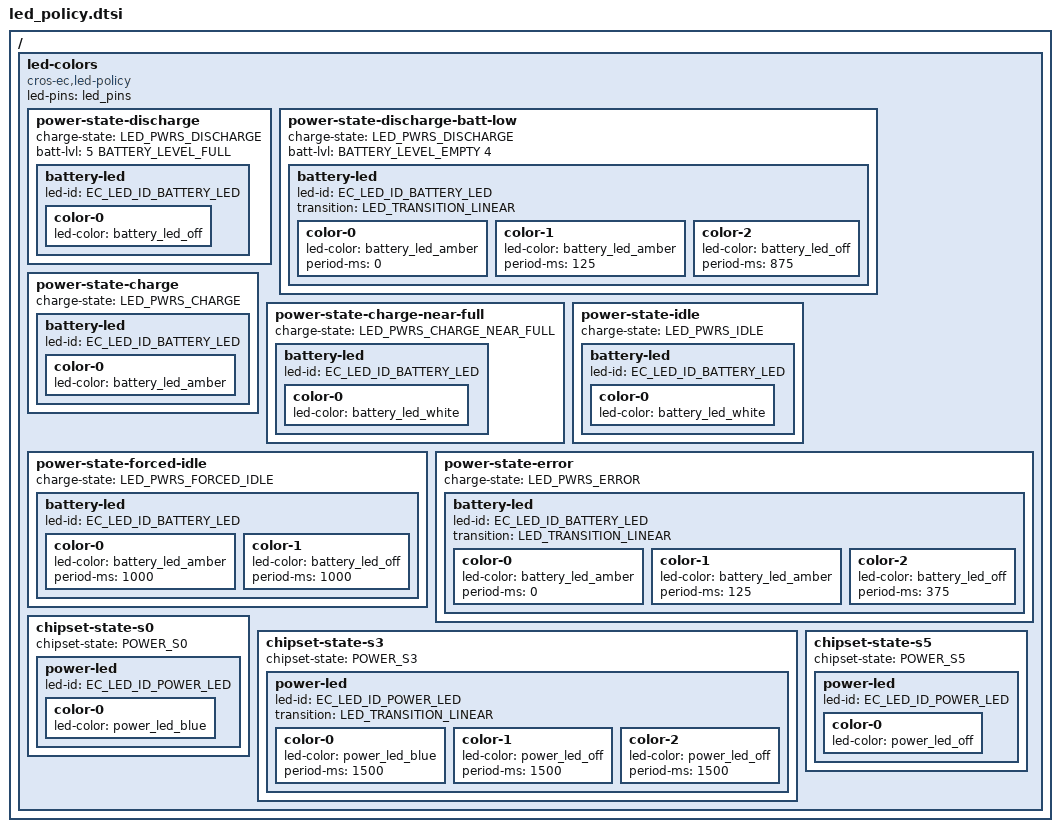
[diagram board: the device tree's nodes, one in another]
#include <dt-bindings/battery.h>

/ {
	led-colors {
		compatible = "cros-ec,led-policy";
		led-pins = <&led_pins>;

		/* --------------------------------------------------
		 * DC MODE (DISCHARGE)
		 * -------------------------------------------------- */

		/* On battery only (discharge): default off */
		power-state-discharge {
			charge-state = "LED_PWRS_DISCHARGE";
			batt-lvl = <5 BATTERY_LEVEL_FULL>;

			battery-led {
				led-id = "EC_LED_ID_BATTERY_LED";

				color-0 {
					led-color = <&battery_led_off>;
				};
			};
		};

		power-state-discharge-batt-low {
			charge-state = "LED_PWRS_DISCHARGE";
			batt-lvl = <BATTERY_LEVEL_EMPTY 4>;

			battery-led {
				led-id = "EC_LED_ID_BATTERY_LED";

				transition = "LED_TRANSITION_LINEAR";

				/* Amber slow flashing */
				color-0 {
					led-color = <&battery_led_amber>;
					period-ms = <0>;
				};
				color-1 {
					led-color = <&battery_led_amber>;
					period-ms = <125>;
				};
				color-2 {
					led-color = <&battery_led_off>;
					period-ms = <875>;
				};
			};
		};


		/* --------------------------------------------------
		 * AC MODE
		 * -------------------------------------------------- */

		/* LED_PWRS_CHARGE: Battery Amber solid (even in suspend) */
		power-state-charge {
			charge-state = "LED_PWRS_CHARGE";

			battery-led {
				led-id = "EC_LED_ID_BATTERY_LED";
				color-0 {
					led-color = <&battery_led_amber>;
				};
			};
		};

		/* LED_PWRS_CHARGE_NEAR_FULL: Battery White solid */
		power-state-charge-near-full {
			charge-state = "LED_PWRS_CHARGE_NEAR_FULL";

			battery-led {
				led-id = "EC_LED_ID_BATTERY_LED";
				color-0 {
					led-color = <&battery_led_white>;
				};
			};
		};

		/* LED_PWRS_IDLE: External power in IDLE -> Battery White solid */
		power-state-idle {
			charge-state = "LED_PWRS_IDLE";

			battery-led {
				led-id = "EC_LED_ID_BATTERY_LED";
				color-0 {
					led-color = <&battery_led_white>;
				};
			};
		};

		/* LED_PWRS_FORCED_IDLE */
		power-state-forced-idle {
			charge-state = "LED_PWRS_FORCED_IDLE";

			battery-led {
				led-id = "EC_LED_ID_BATTERY_LED";

				/* Amber 1s on */
				color-0 {
					led-color = <&battery_led_amber>;
					period-ms = <1000>;
				};
				/* Off 1s */
				color-1 {
					led-color = <&battery_led_off>;
					period-ms = <1000>;
				};
			};
		};

		/* LED_PWRS_ERROR */
		power-state-error {
			charge-state = "LED_PWRS_ERROR";

			battery-led {
				led-id = "EC_LED_ID_BATTERY_LED";
				transition = "LED_TRANSITION_LINEAR";

				/* Amber fast flashing */
				color-0 {
					led-color = <&battery_led_amber>;
					period-ms = <0>;
				};
				color-1 {
					led-color = <&battery_led_amber>;
					period-ms = <125>;
				};
				color-2 {
					led-color = <&battery_led_off>;
					period-ms = <375>;
				};
			};
		};


		/* --------------------------------------------------
		 * POWER LED (Power/Standby LED, HP LED spec 2.1)
		 * --------------------------------------------------
		 * The LED driver maps both S3 and S0ix to POWER_S3
		 * (CHIPSET_STATE_ANY_SUSPEND), so S3 and S0ix share the same
		 * state, as in the other ocelot projects.
		 *
		 *   S0       : solid blue
		 *   S3/S0ix  : breathing blue
		 *              0% -> 100% (1.5s), 100% -> 0% (1.5s), off (1.5s)
		 *   S4/S5/G3 : off
		 *
		 * The spec also requires the blinking/breathing to be off when
		 * the lid is closed. It cannot be expressed here because
		 * board_led_alt_policy() is owned by the Google Private lightbar
		 * module, so src/led.c gates this policy from board code.
		 */

		/* S0: solid blue, independent of the lid state */
		chipset-state-s0 {
			chipset-state = "POWER_S0";

			power-led {
				led-id = "EC_LED_ID_POWER_LED";
				color-0 {
					led-color = <&power_led_blue>;
				};
			};
		};

		/* S3/S0ix: blue breathing */
		chipset-state-s3 {
			chipset-state = "POWER_S3";

			power-led {
				led-id = "EC_LED_ID_POWER_LED";
				transition = "LED_TRANSITION_LINEAR";

				/* 0% -> 100% (1500ms) */
				color-0 {
					led-color = <&power_led_blue>;
					period-ms = <1500>;
				};
				/* 100% -> 0% (1500ms) */
				color-1 {
					led-color = <&power_led_off>;
					period-ms = <1500>;
				};
				/* off hold (1500ms) */
				color-2 {
					led-color = <&power_led_off>;
					period-ms = <1500>;
				};
			};
		};

		/* S4/S5/G3: Power off */
		chipset-state-s5 {
			chipset-state = "POWER_S5";

			power-led {
				led-id = "EC_LED_ID_POWER_LED";
				color-0 {
					led-color = <&power_led_off>;
				};
			};
		};
	};
};
